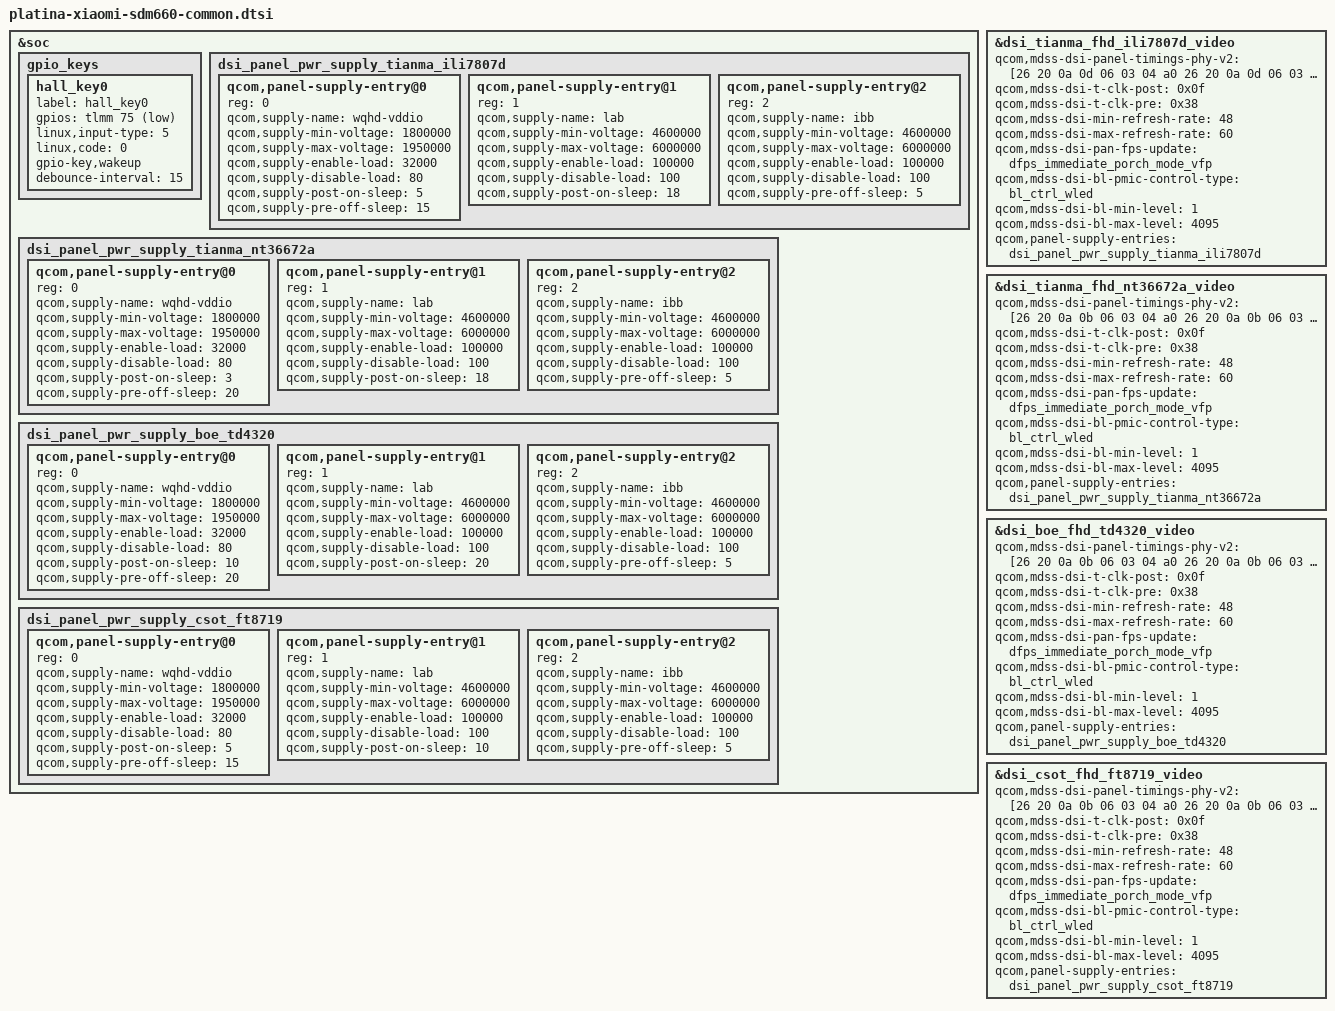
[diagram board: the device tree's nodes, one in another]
/*
 * Copyright (c) 2016-2017, The Linux Foundation. All rights reserved.
 * Copyright (C) 2020 XiaoMi, Inc.
 *
 * This program is free software; you can redistribute it and/or modify
 * it under the terms of the GNU General Public License version 2 and
 * only version 2 as published by the Free Software Foundation.
 *
 * This program is distributed in the hope that it will be useful,
 * but WITHOUT ANY WARRANTY; without even the implied warranty of
 * MERCHANTABILITY or FITNESS FOR A PARTICULAR PURPOSE.  See the
 * GNU General Public License for more details.
 */

&soc {
	gpio_keys {
		hall_key0 {
			label = "hall_key0";
			gpios = <&tlmm 75 0x01>;
			linux,input-type = <5>;
			linux,code = <0>;
			gpio-key,wakeup;
			debounce-interval = <15>;
		};
	};
};

&dsi_tianma_fhd_ili7807d_video {
	qcom,mdss-dsi-panel-timings-phy-v2 = [26 20 0a 0d 06 03 04 a0
		26 20 0a 0d 06 03 04 a0
		26 20 0a 0d 06 03 04 a0
		26 20 0a 0d 06 03 04 a0
		26 21 0a 0b 06 03 04 a0];
	qcom,mdss-dsi-t-clk-post = <0x0f>;
	qcom,mdss-dsi-t-clk-pre = <0x38>;
	qcom,mdss-dsi-min-refresh-rate = <48>;
	qcom,mdss-dsi-max-refresh-rate = <60>;
	qcom,mdss-dsi-pan-fps-update = "dfps_immediate_porch_mode_vfp";
	qcom,mdss-dsi-bl-pmic-control-type = "bl_ctrl_wled";
	qcom,mdss-dsi-bl-min-level = <1>;
	qcom,mdss-dsi-bl-max-level = <4095>;
	qcom,panel-supply-entries = <&dsi_panel_pwr_supply_tianma_ili7807d>;
};

&dsi_tianma_fhd_nt36672a_video {
	qcom,mdss-dsi-panel-timings-phy-v2 = [26 20 0a 0b 06 03 04 a0
		26 20 0a 0b 06 03 04 a0
		26 20 0a 0b 06 03 04 a0
		26 20 0a 0b 06 03 04 a0
		26 21 0a 0b 06 03 04 a0];
	qcom,mdss-dsi-t-clk-post = <0x0f>;
	qcom,mdss-dsi-t-clk-pre = <0x38>;
	qcom,mdss-dsi-min-refresh-rate = <48>;
	qcom,mdss-dsi-max-refresh-rate = <60>;
	qcom,mdss-dsi-pan-fps-update = "dfps_immediate_porch_mode_vfp";
	qcom,mdss-dsi-bl-pmic-control-type = "bl_ctrl_wled";
	qcom,mdss-dsi-bl-min-level = <1>;
	qcom,mdss-dsi-bl-max-level = <4095>;
	qcom,panel-supply-entries = <&dsi_panel_pwr_supply_tianma_nt36672a>;
};

&dsi_boe_fhd_td4320_video {
	qcom,mdss-dsi-panel-timings-phy-v2 = [26 20 0a 0b 06 03 04 a0
		26 20 0a 0b 06 03 04 a0
		26 20 0a 0b 06 03 04 a0
		26 20 0a 0b 06 03 04 a0
		26 21 0a 0b 06 03 04 a0];
	qcom,mdss-dsi-t-clk-post = <0x0f>;
	qcom,mdss-dsi-t-clk-pre = <0x38>;
	qcom,mdss-dsi-min-refresh-rate = <48>;
	qcom,mdss-dsi-max-refresh-rate = <60>;
	qcom,mdss-dsi-pan-fps-update = "dfps_immediate_porch_mode_vfp";
	qcom,mdss-dsi-bl-pmic-control-type = "bl_ctrl_wled";
	qcom,mdss-dsi-bl-min-level = <1>;
	qcom,mdss-dsi-bl-max-level = <4095>;
	qcom,panel-supply-entries = <&dsi_panel_pwr_supply_boe_td4320>;
};

&dsi_csot_fhd_ft8719_video {
	qcom,mdss-dsi-panel-timings-phy-v2 = [26 20 0a 0b 06 03 04 a0
		26 20 0a 0b 06 03 04 a0
		26 20 0a 0b 06 03 04 a0
		26 20 0a 0b 06 03 04 a0
		26 21 0a 0b 06 03 04 a0];
	qcom,mdss-dsi-t-clk-post = <0x0f>;
	qcom,mdss-dsi-t-clk-pre = <0x38>;
	qcom,mdss-dsi-min-refresh-rate = <48>;
	qcom,mdss-dsi-max-refresh-rate = <60>;
	qcom,mdss-dsi-pan-fps-update = "dfps_immediate_porch_mode_vfp";
	qcom,mdss-dsi-bl-pmic-control-type = "bl_ctrl_wled";
	qcom,mdss-dsi-bl-min-level = <1>;
	qcom,mdss-dsi-bl-max-level = <4095>;
	qcom,panel-supply-entries = <&dsi_panel_pwr_supply_csot_ft8719>;
};

&soc {
    dsi_panel_pwr_supply_tianma_ili7807d: dsi_panel_pwr_supply_tianma_ili7807d {
		#address-cells = <1>;
		#size-cells = <0>;

		qcom,panel-supply-entry@0 {
			reg = <0>;
			qcom,supply-name = "wqhd-vddio";
			qcom,supply-min-voltage = <1800000>;
			qcom,supply-max-voltage = <1950000>;
			qcom,supply-enable-load = <32000>;
			qcom,supply-disable-load = <80>;
			qcom,supply-post-on-sleep = <5>;
			qcom,supply-pre-off-sleep = <15>;
		};

		qcom,panel-supply-entry@1 {
			reg = <1>;
			qcom,supply-name = "lab";
			qcom,supply-min-voltage = <4600000>;
			qcom,supply-max-voltage = <6000000>;
			qcom,supply-enable-load = <100000>;
			qcom,supply-disable-load = <100>;
			qcom,supply-post-on-sleep = <18>;
		};

		qcom,panel-supply-entry@2 {
			reg = <2>;
			qcom,supply-name = "ibb";
			qcom,supply-min-voltage = <4600000>;
			qcom,supply-max-voltage = <6000000>;
			qcom,supply-enable-load = <100000>;
			qcom,supply-disable-load = <100>;
			qcom,supply-pre-off-sleep = <5>;
		};
	};

	dsi_panel_pwr_supply_tianma_nt36672a: dsi_panel_pwr_supply_tianma_nt36672a {
		#address-cells = <1>;
		#size-cells = <0>;

		qcom,panel-supply-entry@0 {
			reg = <0>;
			qcom,supply-name = "wqhd-vddio";
			qcom,supply-min-voltage = <1800000>;
			qcom,supply-max-voltage = <1950000>;
			qcom,supply-enable-load = <32000>;
			qcom,supply-disable-load = <80>;
			qcom,supply-post-on-sleep = <3>;
			qcom,supply-pre-off-sleep = <20>;
		};

		qcom,panel-supply-entry@1 {
			reg = <1>;
			qcom,supply-name = "lab";
			qcom,supply-min-voltage = <4600000>;
			qcom,supply-max-voltage = <6000000>;
			qcom,supply-enable-load = <100000>;
			qcom,supply-disable-load = <100>;
			qcom,supply-post-on-sleep = <18>;
		};

		qcom,panel-supply-entry@2 {
			reg = <2>;
			qcom,supply-name = "ibb";
			qcom,supply-min-voltage = <4600000>;
			qcom,supply-max-voltage = <6000000>;
			qcom,supply-enable-load = <100000>;
			qcom,supply-disable-load = <100>;
			qcom,supply-pre-off-sleep = <5>;
		};
	};

	dsi_panel_pwr_supply_boe_td4320: dsi_panel_pwr_supply_boe_td4320{
		#address-cells = <1>;
		#size-cells = <0>;

		qcom,panel-supply-entry@0 {
			reg = <0>;
			qcom,supply-name = "wqhd-vddio";
			qcom,supply-min-voltage = <1800000>;
			qcom,supply-max-voltage = <1950000>;
			qcom,supply-enable-load = <32000>;
			qcom,supply-disable-load = <80>;
			qcom,supply-post-on-sleep = <10>;
			qcom,supply-pre-off-sleep = <20>;
		};

		qcom,panel-supply-entry@1 {
			reg = <1>;
			qcom,supply-name = "lab";
			qcom,supply-min-voltage = <4600000>;
			qcom,supply-max-voltage = <6000000>;
			qcom,supply-enable-load = <100000>;
			qcom,supply-disable-load = <100>;
			qcom,supply-post-on-sleep = <20>;
		};

		qcom,panel-supply-entry@2 {
			reg = <2>;
			qcom,supply-name = "ibb";
			qcom,supply-min-voltage = <4600000>;
			qcom,supply-max-voltage = <6000000>;
			qcom,supply-enable-load = <100000>;
			qcom,supply-disable-load = <100>;
			qcom,supply-pre-off-sleep = <5>;
		};
	};

	dsi_panel_pwr_supply_csot_ft8719: dsi_panel_pwr_supply_csot_ft8719{
		#address-cells = <1>;
		#size-cells = <0>;

		qcom,panel-supply-entry@0 {
			reg = <0>;
			qcom,supply-name = "wqhd-vddio";
			qcom,supply-min-voltage = <1800000>;
			qcom,supply-max-voltage = <1950000>;
			qcom,supply-enable-load = <32000>;
			qcom,supply-disable-load = <80>;
			qcom,supply-post-on-sleep = <5>;
			qcom,supply-pre-off-sleep = <15>;
		};

		qcom,panel-supply-entry@1 {
			reg = <1>;
			qcom,supply-name = "lab";
			qcom,supply-min-voltage = <4600000>;
			qcom,supply-max-voltage = <6000000>;
			qcom,supply-enable-load = <100000>;
			qcom,supply-disable-load = <100>;
			qcom,supply-post-on-sleep = <10>;
		};

		qcom,panel-supply-entry@2 {
			reg = <2>;
			qcom,supply-name = "ibb";
			qcom,supply-min-voltage = <4600000>;
			qcom,supply-max-voltage = <6000000>;
			qcom,supply-enable-load = <100000>;
			qcom,supply-disable-load = <100>;
			qcom,supply-pre-off-sleep = <5>;
		};
	};
};
